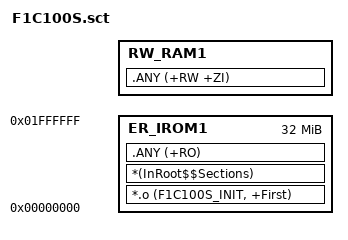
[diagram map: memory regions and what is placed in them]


LR_IROM1 0x00000000 0x2000000  {    ; load region size_region
    ER_IROM1 0x00000000 0x2000000  {  ; load address = execution address
        *.o (F1C100S_INIT, +First)
        *(InRoot$$Sections)
        .ANY (+RO)
    }
    RW_RAM1 +0  {  ; RW_RAM1 start address is after ER_ROM1
        .ANY (+RW +ZI)
    }
}
